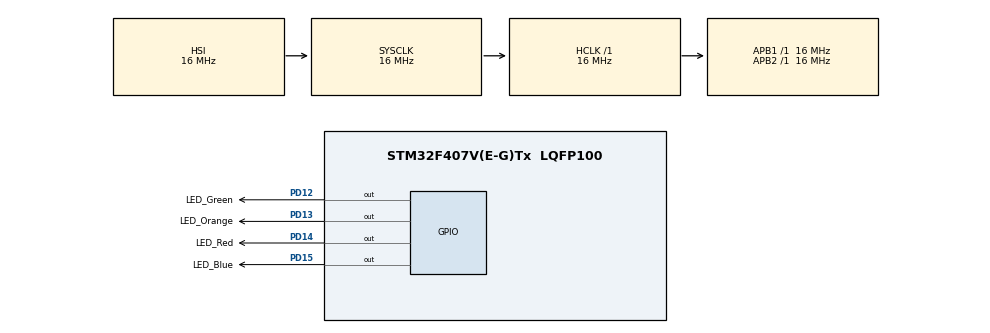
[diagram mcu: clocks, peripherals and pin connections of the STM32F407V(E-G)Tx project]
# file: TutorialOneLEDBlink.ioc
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Mcu.Family=STM32F4
Mcu.Name=STM32F407V(E-G)Tx
Mcu.Package=LQFP100
NVIC.PVD_IRQn=true\:0\:0\:false\:false\:true\:true
NVIC.PriorityGroup=NVIC_PRIORITYGROUP_4
PA13.Mode=Serial_Wire
PA13.Signal=SYS_JTMS-SWDIO
PA14.Mode=Serial_Wire
PA14.Signal=SYS_JTCK-SWCLK
PD12.GPIO_Label=LED_Green
PD12.Signal=GPIO_Output
PD13.GPIO_Label=LED_Orange
PD13.Signal=GPIO_Output
PD14.GPIO_Label=LED_Red
PD14.Signal=GPIO_Output
PD15.GPIO_Label=LED_Blue
PD15.Signal=GPIO_Output
ProjectManager.HeapSize=0x200
ProjectManager.StackSize=0x400
ProjectManager.TargetToolchain=SW4STM32
RCC.AHBFreq_Value=16000000
RCC.APB1Freq_Value=16000000
RCC.APB2Freq_Value=16000000
RCC.CortexFreq_Value=16000000
RCC.HSE_VALUE=25000000
RCC.HSI_VALUE=16000000
RCC.LSE_VALUE=32768
RCC.SYSCLKFreq_VALUE=16000000
RCC.VCOOutputFreq_Value=192000000
board=custom

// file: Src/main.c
/* USER CODE BEGIN Header */
/**
  ******************************************************************************
  * @file           : main.c
  * @brief          : Main program body
  ******************************************************************************
  ** This notice applies to any and all portions of this file
  * that are not between comment pairs USER CODE BEGIN and
  * USER CODE END. Other portions of this file, whether
  * inserted by the user or by software development tools
  * are owned by their respective copyright owners.
  *
  * COPYRIGHT(c) 2019 STMicroelectronics
  *
  * Redistribution and use in source and binary forms, with or without modification,
  * are permitted provided that the following conditions are met:
  *   1. Redistributions of source code must retain the above copyright notice,
  *      this list of conditions and the following disclaimer.
  *   2. Redistributions in binary form must reproduce the above copyright notice,
  *      this list of conditions and the following disclaimer in the documentation
  *      and/or other materials provided with the distribution.
  *   3. Neither the name of STMicroelectronics nor the names of its contributors
  *      may be used to endorse or promote products derived from this software
  *      without specific prior written permission.
  *
  * THIS SOFTWARE IS PROVIDED BY THE COPYRIGHT HOLDERS AND CONTRIBUTORS "AS IS"
  * AND ANY EXPRESS OR IMPLIED WARRANTIES, INCLUDING, BUT NOT LIMITED TO, THE
  * IMPLIED WARRANTIES OF MERCHANTABILITY AND FITNESS FOR A PARTICULAR PURPOSE ARE
  * DISCLAIMED. IN NO EVENT SHALL THE COPYRIGHT HOLDER OR CONTRIBUTORS BE LIABLE
  * FOR ANY DIRECT, INDIRECT, INCIDENTAL, SPECIAL, EXEMPLARY, OR CONSEQUENTIAL
  * DAMAGES (INCLUDING, BUT NOT LIMITED TO, PROCUREMENT OF SUBSTITUTE GOODS OR
  * SERVICES; LOSS OF USE, DATA, OR PROFITS; OR BUSINESS INTERRUPTION) HOWEVER
  * CAUSED AND ON ANY THEORY OF LIABILITY, WHETHER IN CONTRACT, STRICT LIABILITY,
  * OR TORT (INCLUDING NEGLIGENCE OR OTHERWISE) ARISING IN ANY WAY OUT OF THE USE
  * OF THIS SOFTWARE, EVEN IF ADVISED OF THE POSSIBILITY OF SUCH DAMAGE.
  *
  ******************************************************************************
  */
/* USER CODE END Header */

#include "main.h"

void SystemClock_Config(void);
static void MX_GPIO_Init(void);

/* USER CODE BEGIN 0 */
void sleep(int time)
{
	for(size_t i = 0; i <= time; i++);
}
/* USER CODE END 0 */

int main(void)
{

  /* MCU Configuration--------------------------------------------------------*/

  /* Reset of all peripherals, Initializes the Flash interface and the Systick. */
  HAL_Init();

  /* USER CODE BEGIN Init */
  HAL_GPIO_Init(LED_Orange_GPIO_Port, LED_Orange_Pin);
  HAL_GPIO_Init(LED_Blue_GPIO_Port, LED_Blue_Pin);
  HAL_GPIO_Init(LED_Green_GPIO_Port, LED_Green_Pin);
  HAL_GPIO_Init(LED_Red_GPIO_Port, LED_Red_Pin);
  /* USER CODE END Init */

  /* Configure the system clock */
  SystemClock_Config();

  /* Initialize all configured peripherals */
  MX_GPIO_Init();

  /* Infinite loop */
  while (1)
  {
	  HAL_GPIO_TogglePin(LED_Orange_GPIO_Port, LED_Orange_Pin);
	  HAL_GPIO_TogglePin(LED_Blue_GPIO_Port, LED_Blue_Pin);
	  HAL_GPIO_TogglePin(LED_Green_GPIO_Port, LED_Green_Pin);
	  HAL_GPIO_TogglePin(LED_Red_GPIO_Port, LED_Red_Pin);
	  Sleep(1000000);
  }
}

void SystemClock_Config(void)
{
  RCC_OscInitTypeDef RCC_OscInitStruct = {0};
  RCC_ClkInitTypeDef RCC_ClkInitStruct = {0};

  /**Configure the main internal regulator output voltage
  */
  __HAL_RCC_PWR_CLK_ENABLE();
  __HAL_PWR_VOLTAGESCALING_CONFIG(PWR_REGULATOR_VOLTAGE_SCALE1);
  /**Initializes the CPU, AHB and APB busses clocks
  */
  RCC_OscInitStruct.OscillatorType = RCC_OSCILLATORTYPE_HSI;
  RCC_OscInitStruct.HSIState = RCC_HSI_ON;
  RCC_OscInitStruct.HSICalibrationValue = RCC_HSICALIBRATION_DEFAULT;
  RCC_OscInitStruct.PLL.PLLState = RCC_PLL_NONE;
  if (HAL_RCC_OscConfig(&RCC_OscInitStruct) != HAL_OK)
  {
    Error_Handler();
  }
  /**Initializes the CPU, AHB and APB busses clocks
  */
  RCC_ClkInitStruct.ClockType = RCC_CLOCKTYPE_HCLK|RCC_CLOCKTYPE_SYSCLK
                              |RCC_CLOCKTYPE_PCLK1|RCC_CLOCKTYPE_PCLK2;
  RCC_ClkInitStruct.SYSCLKSource = RCC_SYSCLKSOURCE_HSI;
  RCC_ClkInitStruct.AHBCLKDivider = RCC_SYSCLK_DIV1;
  RCC_ClkInitStruct.APB1CLKDivider = RCC_HCLK_DIV1;
  RCC_ClkInitStruct.APB2CLKDivider = RCC_HCLK_DIV1;

  if (HAL_RCC_ClockConfig(&RCC_ClkInitStruct, FLASH_LATENCY_0) != HAL_OK)
  {
    Error_Handler();
  }
}

static void MX_GPIO_Init(void)
{
  GPIO_InitTypeDef GPIO_InitStruct = {0};

  /* GPIO Ports Clock Enable */
  __HAL_RCC_GPIOD_CLK_ENABLE();
  __HAL_RCC_GPIOA_CLK_ENABLE();

  /*Configure GPIO pin Output Level */
  HAL_GPIO_WritePin(GPIOD, LED_Green_Pin|LED_Orange_Pin|LED_Red_Pin|LED_Blue_Pin, GPIO_PIN_RESET);

  /*Configure GPIO pins : LED_Green_Pin LED_Orange_Pin LED_Red_Pin LED_Blue_Pin */
  GPIO_InitStruct.Pin = LED_Green_Pin|LED_Orange_Pin|LED_Red_Pin|LED_Blue_Pin;
  GPIO_InitStruct.Mode = GPIO_MODE_OUTPUT_PP;
  GPIO_InitStruct.Pull = GPIO_NOPULL;
  GPIO_InitStruct.Speed = GPIO_SPEED_FREQ_LOW;
  HAL_GPIO_Init(GPIOD, &GPIO_InitStruct);

}

void Error_Handler(void)
{
}

/************************ (C) COPYRIGHT STMicroelectronics *****END OF FILE****/
